# SIMG301M104LIH register map
Vendor: Silicon Labs; Series: Si; File version: B
Registers are 32-bit, read-write, reset 0x0 unless marked. A register's access mark holds for its fields unless they carry their own. Offsets are from the block's base; [hi:lo] are bit positions; 'fields as' and 'values as' point back to an identical list.

## PCNT0_NS — PCNT0_NS Registers
Base 0x40040000
Same registers: PCNT0_S 0x50040000
0x00 IPVERSION ro reset 0x1
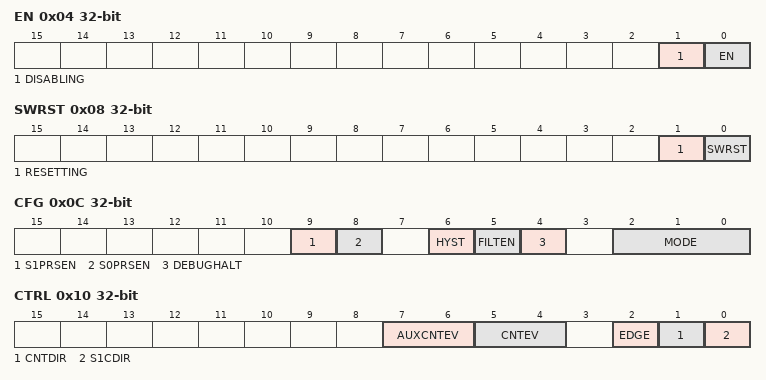
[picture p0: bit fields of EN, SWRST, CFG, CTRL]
0x04 EN
  [1] DISABLING ro — Disablement busy status
  [0] EN — PCNT Module Enable
0x08 SWRST
  [1] RESETTING ro — Software reset busy status
  [0] SWRST wo — Software reset command
0x0C CFG
  [9] S1PRSEN — S1IN PRS Enable
  [8] S0PRSEN — S0IN PRS Enable
  [6] HYST — Enable Hysteresis
  [5] FILTEN — Enable Digital Pulse Width Filter
  [4] DEBUGHALT — Debug Mode Halt Enable
    0=DISABLE (PCNT is running in debug mode.); 1=ENABLE (PCNT is frozen in debug mode.)
  [2:0] MODE — Mode Select
    0=OVSSINGLE (Single input EM23GRPACLK oversampling mode); 1=EXTCLKSINGLE (Externally clocked single input counter mode); 2=EXTCLKQUAD (Externally clocked quadrature decoder mode); 3=OVSQUAD1X (EM23GRPACLK oversampling quadrature decoder 1X mode); 4=OVSQUAD2X (EM23GRPACLK oversampling quadrature decoder 2X mode); 5=OVSQUAD4X (EM23GRPACLK oversampling quadrature decoder 4X mode)
0x10 CTRL
  [7:6] AUXCNTEV — Controls When the Aux Counter Counts
    0=BOTH (Counts up on both up-count and down-count events.); 1=UP (Counts up on up-count events.); 2=DOWN (Counts up on down-count events.)
  [5:4] CNTEV — Controls When the Counter Counts
    0=BOTH (Counts up on up-count and down on down-count events.); 1=UP (Only counts up on up-count events.); 2=DOWN (Only counts down on down-count events.)
  [2] EDGE — Edge Select
    0=POS (Positive edges on the PCNTn_S0IN inputs are counted in OVSSINGLE mode. Does not invert PCNTn_S1IN input in OVSSINGLE and EXTCLKSINGLE modes); 1=NEG (Negative edges on the PCNTn_S0IN inputs are counted in OVSSINGLE mode. Inverts the PCNTn_S1IN input in OVSSINGLE and EXTCLKSINGLE modes)
  [1] CNTDIR — Non-Quadrature Mode Counter Direction Co
    0=UP (Up counter mode.); 1=DOWN (Down counter mode.)
  [0] S1CDIR — Count Direction Determined By S1
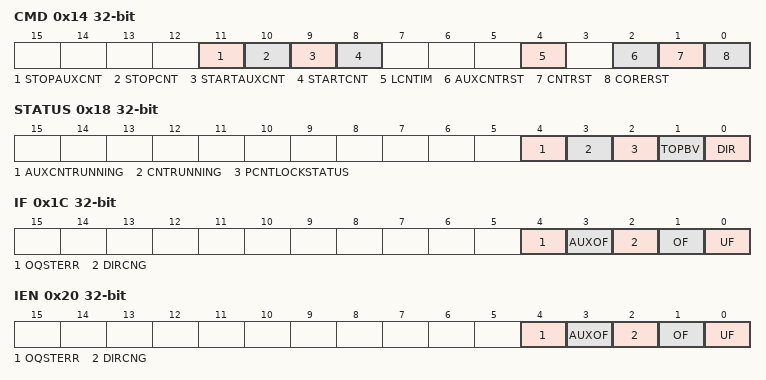
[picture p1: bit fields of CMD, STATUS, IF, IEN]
0x14 CMD wo
  [11] STOPAUXCNT — Stop Aux Counter
  [10] STOPCNT — Stop Main Counter
  [9] STARTAUXCNT — Start Aux Counter
  [8] STARTCNT — Start Main Counter
  [4] LCNTIM — Load CNT Immediately
  [2] AUXCNTRST — AUXCNT Reset
  [1] CNTRST — CNT Reset
  [0] CORERST — PCNT Clock Domain Reset
0x18 STATUS ro
  [4] AUXCNTRUNNING — Aux Counter running status
  [3] CNTRUNNING — Main Counter running status
  [2] PCNTLOCKSTATUS — Lock Status
    0=UNLOCKED (PCNT registers are unlocked); 1=LOCKED (PCNT registers are locked)
  [1] TOPBV — TOP Buffer Valid
  [0] DIR — Current Counter Direction
    0=UP (Up counter mode (clockwise in EXTCLKQUAD mode with the EDGE bit in PCNTn_CTRL set to 0).); 1=DOWN (Down counter mode.)
0x1C IF
  [4] OQSTERR — Oversampling Quad State Err Int Flag
  [3] AUXOF — Auxiliary Overflow Interrupt Read Flag
  [2] DIRCNG — Direction Change Detect Interrupt Flag
  [1] OF — Overflow Interrupt Read Flag
  [0] UF — Underflow Interrupt Read Flag
0x20 IEN
  fields as IF
0x24 CNT ro
  [15:0] CNT — Counter Value
0x28 AUXCNT ro
  [15:0] AUXCNT — Auxiliary Counter Value
0x2C TOP reset 0xFF
  [15:0] TOP — Counter Top Value
0x30 TOPB reset 0xFF
  [15:0] TOPB — Counter Top Buffer Register
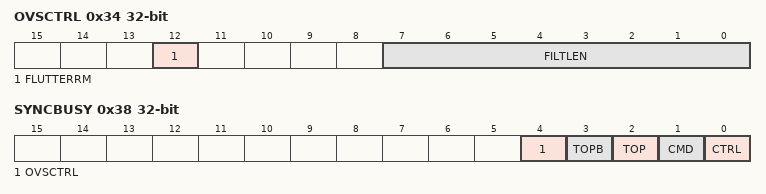
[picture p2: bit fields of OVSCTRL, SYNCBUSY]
0x34 OVSCTRL
  [12] FLUTTERRM — Flutter Remove
  [7:0] FILTLEN — Configure Filter Length for Inputs S0IN
0x38 SYNCBUSY ro
  [4] OVSCTRL — OVSCTRL Register Busy
  [3] TOPB — TOPB Register Busy
  [2] TOP — TOP Register Busy
  [1] CMD — CMD Register Busy
  [0] CTRL — CTRL Register Busy
0x3C LOCK wo
  [15:0] PCNTLOCKKEY — Configuration Lock Key
    0xA7E0=UNLOCK (Write to unock PCNT lockable registers)

## PIXELRZ0_NS — PIXELRZ0_NS Registers
Base 0x40860000
Same registers: PIXELRZ1_NS 0x4088C000, PIXELRZ0_S 0x50860000, PIXELRZ1_S 0x5088C000
0x00 IPVERSION ro reset 0x1
  [31:0] IPVERSION — IP version ID
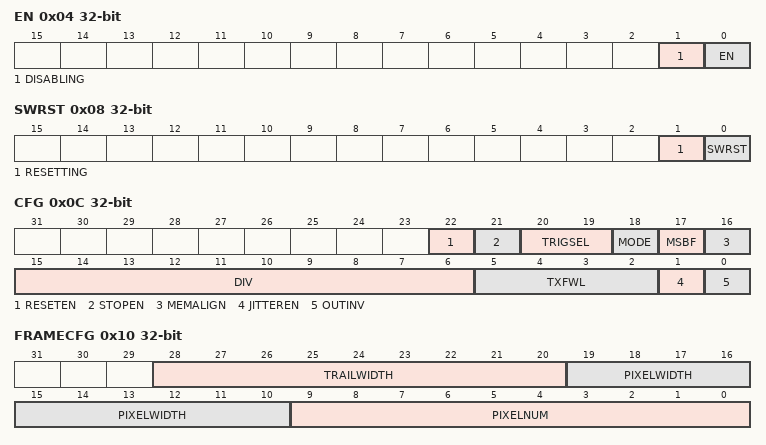
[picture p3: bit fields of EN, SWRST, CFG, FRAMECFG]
0x04 EN
  [1] DISABLING ro — Disablment busy status
  [0] EN — module enable
    0=DISABLE (Disable Peripheral Clock); 1=ENABLE (Enable Peripheral Clock)
0x08 SWRST
  [1] RESETTING ro — Reset busy status
  [0] SWRST wo — Software Reset bit
0x0C CFG
  [22] RESETEN — RESET Symbol Enable
    0=DISABLE (RESET symbols will not be sent); 1=ENABLE (RESET symbols will be sent at the end of each frame)
  [21] STOPEN — STOP Symbol Enable
    0=DISABLE (STOP symbols will not be sent); 1=ENABLE (STOP symbols will be sent at the end of each pixel)
  [20:19] TRIGSEL — Trigger Select
    0=SW (Software trigger mode); 1=AUTO (Auto trigger mode); 2=PRS (PRS trigger mode)
  [18] MODE — Bus Mode
    0=SEQUENTIAL (PIXELRZ formats data for sequential LED connection); 1=PARALLEL (PIXELRZ formats data for parallel LED connection)
  [17] MSBF — MSB First Enable
    0=LSB (Data will be sent LSB-first); 1=MSB (Data will be sent MSB-first)
  [16] MEMALIGN — Memory Alignment
    0=ALIGN8 (Use 8-bit alignment in FIFO); 1=ALIGN32 (Use 32-bit alignment in FIFO)
  [15:6] DIV — Clock Prescaler
  [5:2] TXFWL — TXDATA FIFO Watermark Level
  [1] JITTEREN — Jitter Enable
    0=DISABLE (Jitter generation is disabled); 1=ENABLE (Jitter generation is enabled)
  [0] OUTINV — Invert Output
    0=NORMAL (Output will be logic 0 during low times and logic 1 during high times); 1=INVERT (Output will be logic 1 during low times and logic 0 during high times)
0x10 FRAMECFG
  [28:20] TRAILWIDTH — Trail Data Width
  [19:10] PIXELWIDTH — Pixel Data Width
  [9:0] PIXELNUM — Pixels per Frame
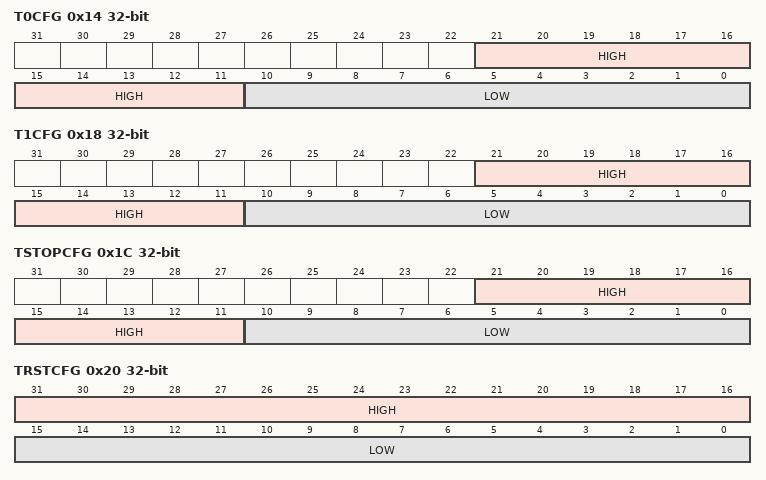
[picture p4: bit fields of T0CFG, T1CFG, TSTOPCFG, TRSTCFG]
0x14 T0CFG
  [21:11] HIGH — Zero symbol High Time
  [10:0] LOW — Zero symbol Low Time
0x18 T1CFG
  [21:11] HIGH — One Symbol High Time
  [10:0] LOW — One Symbol Low Time
0x1C TSTOPCFG
  [21:11] HIGH — Stop Symbol High Time
  [10:0] LOW — Stop Symbol Low Time
0x20 TRSTCFG
  [31:16] HIGH — Reset Symbol High Time
  [15:0] LOW — Reset Symbol Low Time
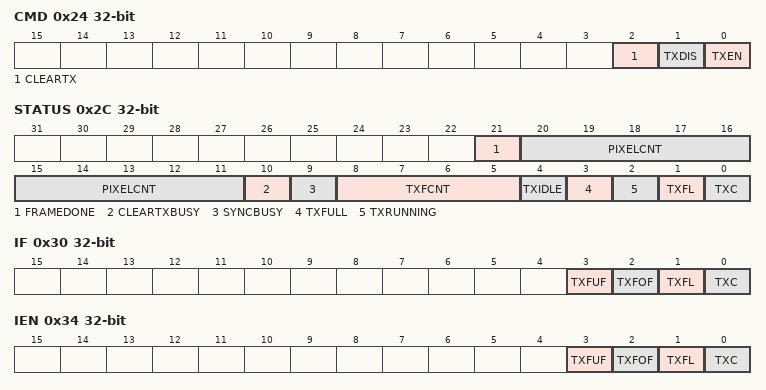
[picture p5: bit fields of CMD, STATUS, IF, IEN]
0x24 CMD wo
  [2] CLEARTX — Clear TX fifo
  [1] TXDIS — Send stop condition
  [0] TXEN — Send start condition
0x28 TXDATA wo
  [31:0] TXDATA — TX Data FIFO
0x2C STATUS ro
  [21] FRAMEDONE
  [20:11] PIXELCNT — Pixel Count
  [10] CLEARTXBUSY — Clear TX Command Busy
  [9] SYNCBUSY
  [8:5] TXFCNT — FIFO Count
  [4] TXIDLE — Transmitter Idle
  [3] TXFULL — TX FIFO full
  [2] TXRUNNING — TX in Progress
  [1] TXFL — TX FIFO Watermark
  [0] TXC — TX Complete
0x30 IF
  [3] TXFUF — Underflow
  [2] TXFOF — Overflow
  [1] TXFL — Reached watermark
  [0] TXC — Transmission complete
0x34 IEN
  [3] TXFUF — Underflow interrupt enable
  [2] TXFOF — Overflow interrupt enable
  [1] TXFL — Reached watermark interrupt enable
  [0] TXC — Transmission complete interrupt enable
